# CC13x0 register map
File version: 2.0
CPU: CM3 r2p1, little endian, no MPU, no FPU, 0x3 interrupt priority bits, 0x0 interrupts
Registers are 32-bit, read-write, reset 0x0 unless marked. A register's access mark holds for its fields unless they carry their own. Offsets are from the block's base; [hi:lo] are bit positions; {n}, {i} and the like mark numbered series; 'fields as' and 'values as' point back to an identical list.

## FCFG1 — Factory configuration area (FCFG1)
Base 0x50001000
0xA0 MISC_CONF_1 ro reset 0xFFFFFF00 — Misc configurations
  [7:0] DEVICE_MINOR_REV
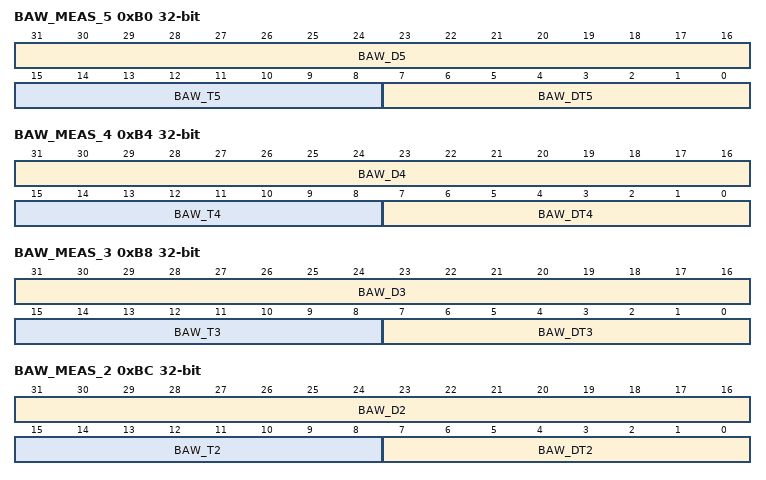
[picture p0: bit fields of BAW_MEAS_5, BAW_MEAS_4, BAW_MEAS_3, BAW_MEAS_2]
0xB0 BAW_MEAS_5 ro — Internal. Only to be used through TI provided API.
  [31:16] BAW_D5, [15:8] BAW_T5, [7:0] BAW_DT5
0xB4 BAW_MEAS_4 ro — Internal. Only to be used through TI provided API.
  [31:16] BAW_D4, [15:8] BAW_T4, [7:0] BAW_DT4
0xB8 BAW_MEAS_3 ro — Internal. Only to be used through TI provided API.
  [31:16] BAW_D3, [15:8] BAW_T3, [7:0] BAW_DT3
0xBC BAW_MEAS_2 ro — Internal. Only to be used through TI provided API.
  [31:16] BAW_D2, [15:8] BAW_T2, [7:0] BAW_DT2
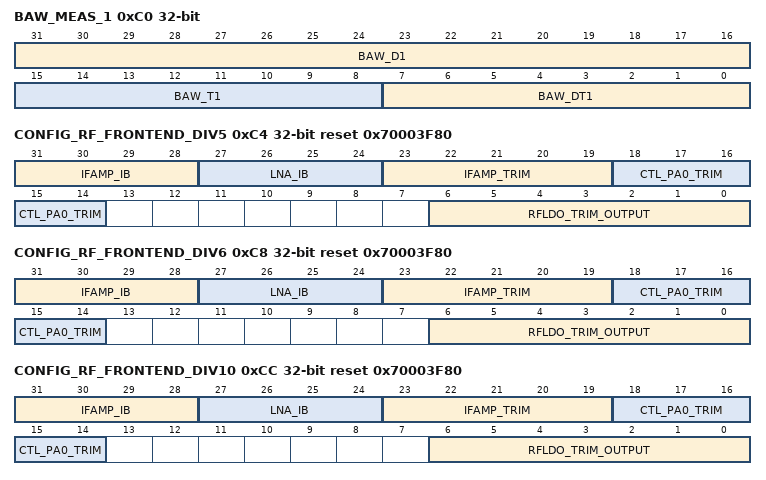
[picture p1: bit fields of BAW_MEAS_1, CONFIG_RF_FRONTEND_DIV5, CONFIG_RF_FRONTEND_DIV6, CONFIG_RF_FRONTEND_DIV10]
0xC0 BAW_MEAS_1 ro — Internal. Only to be used through TI provided API.
  [31:16] BAW_D1, [15:8] BAW_T1, [7:0] BAW_DT1
0xC4 CONFIG_RF_FRONTEND_DIV5 ro reset 0x70003F80 — Internal. Only to be used through TI provided API.
  [31:28] IFAMP_IB, [27:24] LNA_IB, [23:19] IFAMP_TRIM, [18:14] CTL_PA0_TRIM, [6:0] RFLDO_TRIM_OUTPUT
0xC8 CONFIG_RF_FRONTEND_DIV6 ro reset 0x70003F80 — Internal. Only to be used through TI provided API.
  fields as CONFIG_RF_FRONTEND_DIV5
0xCC CONFIG_RF_FRONTEND_DIV10 ro reset 0x70003F80 — Internal. Only to be used through TI provided API.
  fields as CONFIG_RF_FRONTEND_DIV5
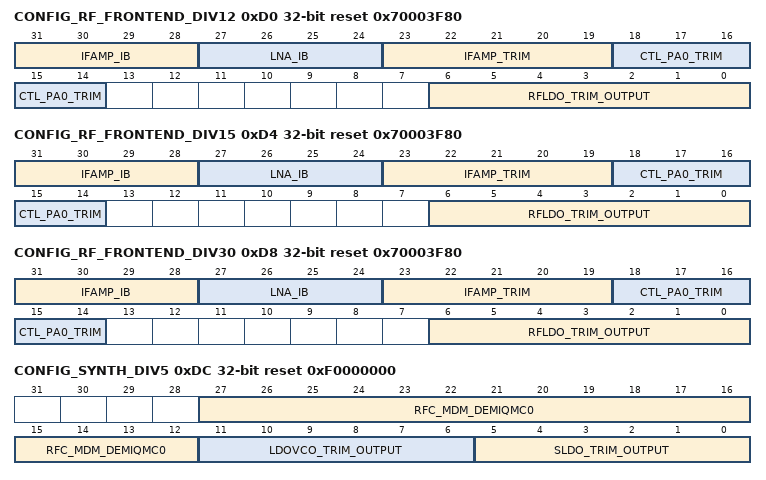
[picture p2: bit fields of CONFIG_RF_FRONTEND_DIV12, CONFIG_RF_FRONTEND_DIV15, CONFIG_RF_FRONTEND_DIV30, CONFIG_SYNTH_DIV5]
0xD0 CONFIG_RF_FRONTEND_DIV12 ro reset 0x70003F80 — Internal. Only to be used through TI provided API.
  fields as CONFIG_RF_FRONTEND_DIV5
0xD4 CONFIG_RF_FRONTEND_DIV15 ro reset 0x70003F80 — Internal. Only to be used through TI provided API.
  fields as CONFIG_RF_FRONTEND_DIV5
0xD8 CONFIG_RF_FRONTEND_DIV30 ro reset 0x70003F80 — Internal. Only to be used through TI provided API.
  fields as CONFIG_RF_FRONTEND_DIV5
0xDC CONFIG_SYNTH_DIV5 ro reset 0xF0000000 — Internal. Only to be used through TI provided API.
  [27:12] RFC_MDM_DEMIQMC0, [11:6] LDOVCO_TRIM_OUTPUT, [5:0] SLDO_TRIM_OUTPUT
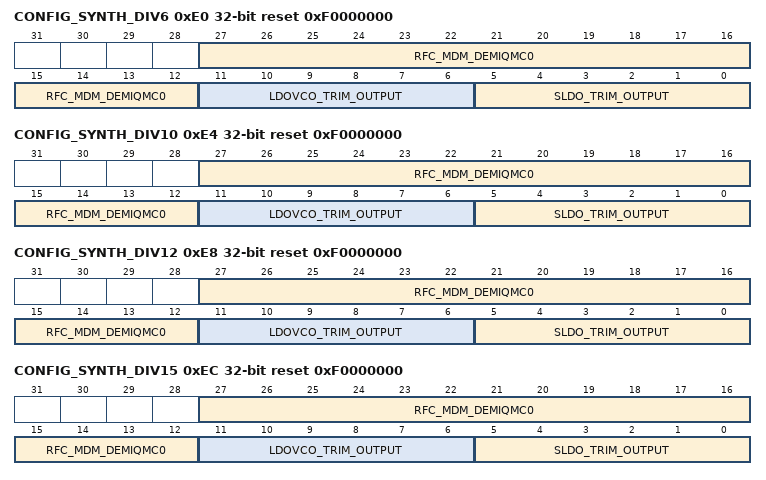
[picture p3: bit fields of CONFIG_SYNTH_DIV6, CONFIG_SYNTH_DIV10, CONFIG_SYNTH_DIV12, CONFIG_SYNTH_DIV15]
0xE0 CONFIG_SYNTH_DIV6 ro reset 0xF0000000 — Internal. Only to be used through TI provided API.
  fields as CONFIG_SYNTH_DIV5
0xE4 CONFIG_SYNTH_DIV10 ro reset 0xF0000000 — Internal. Only to be used through TI provided API.
  fields as CONFIG_SYNTH_DIV5
0xE8 CONFIG_SYNTH_DIV12 ro reset 0xF0000000 — Internal. Only to be used through TI provided API.
  fields as CONFIG_SYNTH_DIV5
0xEC CONFIG_SYNTH_DIV15 ro reset 0xF0000000 — Internal. Only to be used through TI provided API.
  fields as CONFIG_SYNTH_DIV5
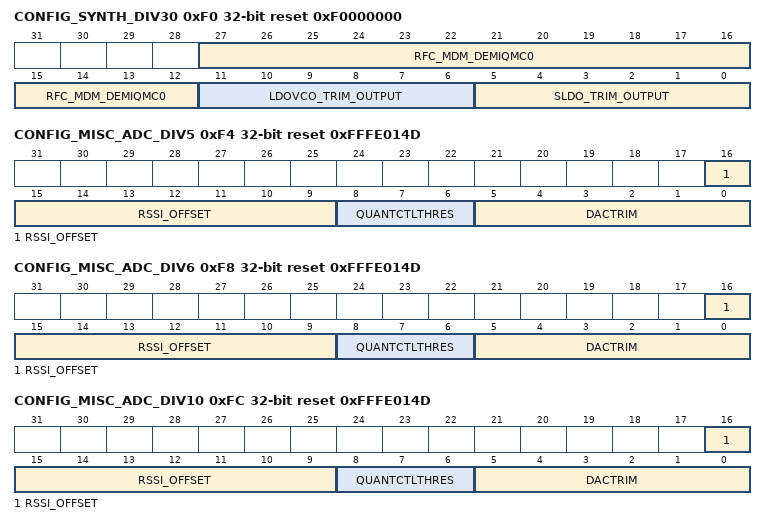
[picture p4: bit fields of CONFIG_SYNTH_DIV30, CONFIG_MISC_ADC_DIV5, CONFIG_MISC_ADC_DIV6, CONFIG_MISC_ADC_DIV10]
0xF0 CONFIG_SYNTH_DIV30 ro reset 0xF0000000 — Internal. Only to be used through TI provided API.
  fields as CONFIG_SYNTH_DIV5
0xF4 CONFIG_MISC_ADC_DIV5 ro reset 0xFFFE014D — Internal. Only to be used through TI provided API.
  [16:9] RSSI_OFFSET, [8:6] QUANTCTLTHRES, [5:0] DACTRIM
0xF8 CONFIG_MISC_ADC_DIV6 ro reset 0xFFFE014D — Internal. Only to be used through TI provided API.
  [16:9] RSSI_OFFSET, [8:6] QUANTCTLTHRES, [5:0] DACTRIM
0xFC CONFIG_MISC_ADC_DIV10 ro reset 0xFFFE014D — Internal. Only to be used through TI provided API.
  [16:9] RSSI_OFFSET, [8:6] QUANTCTLTHRES, [5:0] DACTRIM
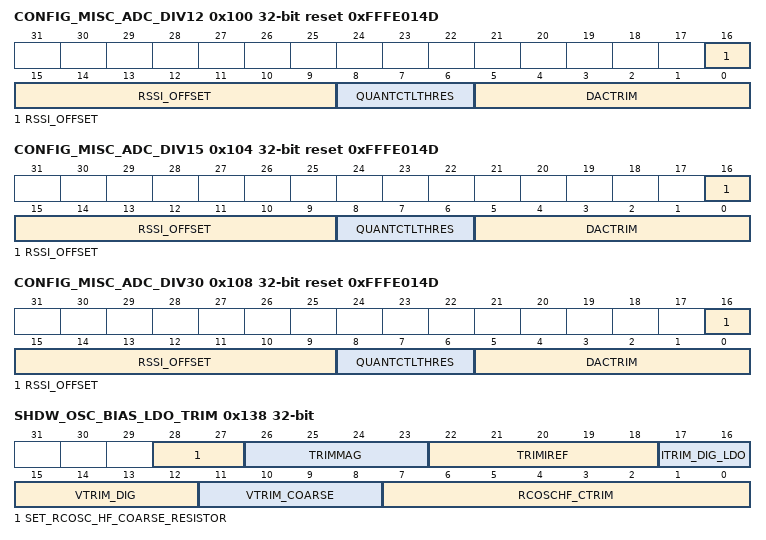
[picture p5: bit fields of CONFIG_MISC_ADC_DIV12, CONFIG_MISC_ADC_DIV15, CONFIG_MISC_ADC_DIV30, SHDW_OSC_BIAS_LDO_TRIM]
0x100 CONFIG_MISC_ADC_DIV12 ro reset 0xFFFE014D — Internal. Only to be used through TI provided API.
  [16:9] RSSI_OFFSET, [8:6] QUANTCTLTHRES, [5:0] DACTRIM
0x104 CONFIG_MISC_ADC_DIV15 ro reset 0xFFFE014D — Internal. Only to be used through TI provided API.
  [16:9] RSSI_OFFSET, [8:6] QUANTCTLTHRES, [5:0] DACTRIM
0x108 CONFIG_MISC_ADC_DIV30 ro reset 0xFFFE014D — Internal. Only to be used through TI provided API.
  [16:9] RSSI_OFFSET, [8:6] QUANTCTLTHRES, [5:0] DACTRIM
{0x118+4i} SHDW_DIE_ID_{i} ro (i=0..3) — Shadow of the DIE_ID_{i} register in eFuse
  [31:0] ID_{32i+31}_{32i}
0x138 SHDW_OSC_BIAS_LDO_TRIM ro — Internal. Only to be used through TI provided API.
  [28:27] SET_RCOSC_HF_COARSE_RESISTOR, [26:23] TRIMMAG, [22:18] TRIMIREF, [17:16] ITRIM_DIG_LDO, [15:12] VTRIM_DIG, [11:8] VTRIM_COARSE, [7:0] RCOSCHF_CTRIM
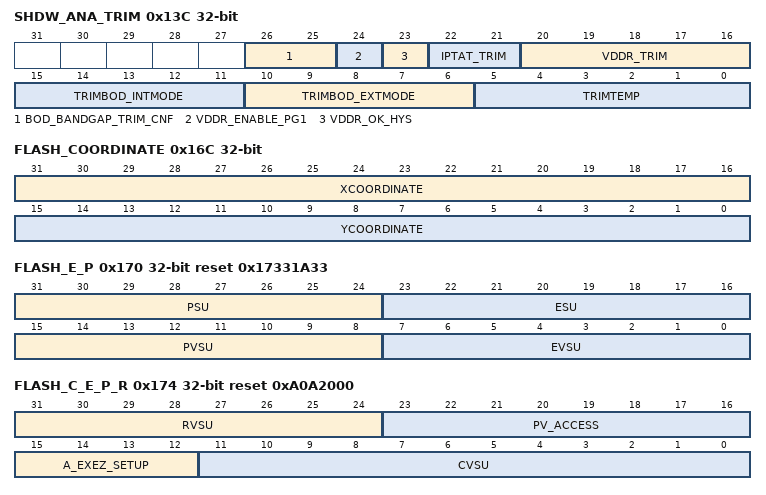
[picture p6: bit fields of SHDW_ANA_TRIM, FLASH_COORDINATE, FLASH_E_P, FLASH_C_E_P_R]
0x13C SHDW_ANA_TRIM ro — Internal. Only to be used through TI provided API.
  [26:25] BOD_BANDGAP_TRIM_CNF, [24] VDDR_ENABLE_PG1, [23] VDDR_OK_HYS, [22:21] IPTAT_TRIM, [20:16] VDDR_TRIM, [15:11] TRIMBOD_INTMODE, [10:6] TRIMBOD_EXTMODE, [5:0] TRIMTEMP
0x164 FLASH_NUMBER ro
  [31:0] LOT_NUMBER
0x16C FLASH_COORDINATE ro
  [31:16] XCOORDINATE, [15:0] YCOORDINATE
0x170 FLASH_E_P ro reset 0x17331A33 — Internal. Only to be used through TI provided API.
  [31:24] PSU, [23:16] ESU, [15:8] PVSU, [7:0] EVSU
0x174 FLASH_C_E_P_R ro reset 0xA0A2000 — Internal. Only to be used through TI provided API.
  [31:24] RVSU, [23:16] PV_ACCESS, [15:12] A_EXEZ_SETUP, [11:0] CVSU
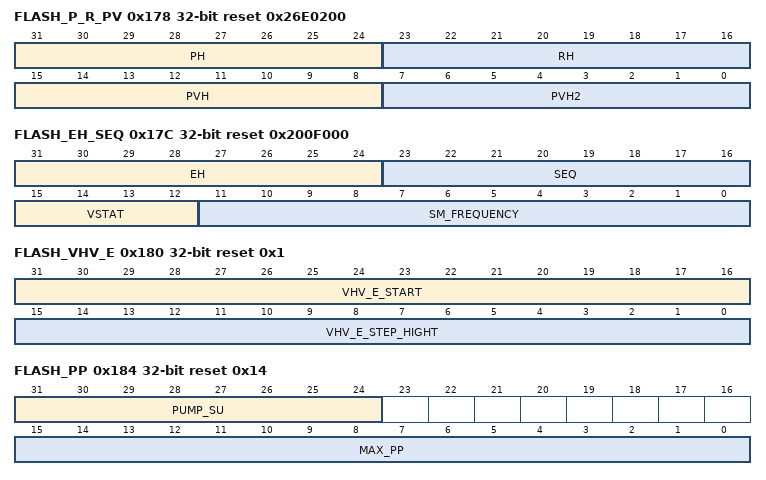
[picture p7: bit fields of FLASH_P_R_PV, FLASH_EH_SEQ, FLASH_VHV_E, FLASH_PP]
0x178 FLASH_P_R_PV ro reset 0x26E0200 — Internal. Only to be used through TI provided API.
  [31:24] PH, [23:16] RH, [15:8] PVH, [7:0] PVH2
0x17C FLASH_EH_SEQ ro reset 0x200F000 — Internal. Only to be used through TI provided API.
  [31:24] EH, [23:16] SEQ, [15:12] VSTAT, [11:0] SM_FREQUENCY
0x180 FLASH_VHV_E ro reset 0x1 — Internal. Only to be used through TI provided API.
  [31:16] VHV_E_START, [15:0] VHV_E_STEP_HIGHT
0x184 FLASH_PP ro reset 0x14 — Internal. Only to be used through TI provided API.
  [31:24] PUMP_SU, [15:0] MAX_PP
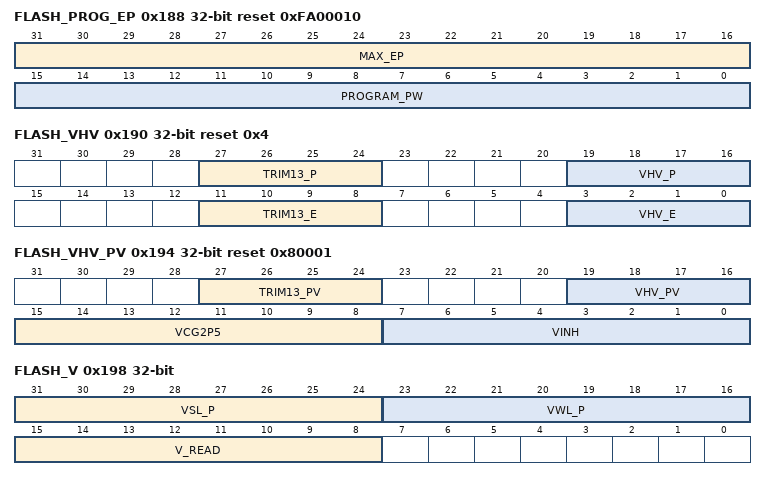
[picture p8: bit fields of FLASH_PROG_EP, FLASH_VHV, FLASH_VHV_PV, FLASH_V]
0x188 FLASH_PROG_EP ro reset 0xFA00010 — Internal. Only to be used through TI provided API.
  [31:16] MAX_EP, [15:0] PROGRAM_PW
0x18C FLASH_ERA_PW ro reset 0xFA0 — Internal. Only to be used through TI provided API.
  [31:0] ERASE_PW
0x190 FLASH_VHV ro reset 0x4 — Internal. Only to be used through TI provided API.
  [27:24] TRIM13_P, [19:16] VHV_P, [11:8] TRIM13_E, [3:0] VHV_E
0x194 FLASH_VHV_PV ro reset 0x80001 — Internal. Only to be used through TI provided API.
  [27:24] TRIM13_PV, [19:16] VHV_PV, [15:8] VCG2P5, [7:0] VINH
0x198 FLASH_V ro — Internal. Only to be used through TI provided API.
  [31:24] VSL_P, [23:16] VWL_P, [15:8] V_READ
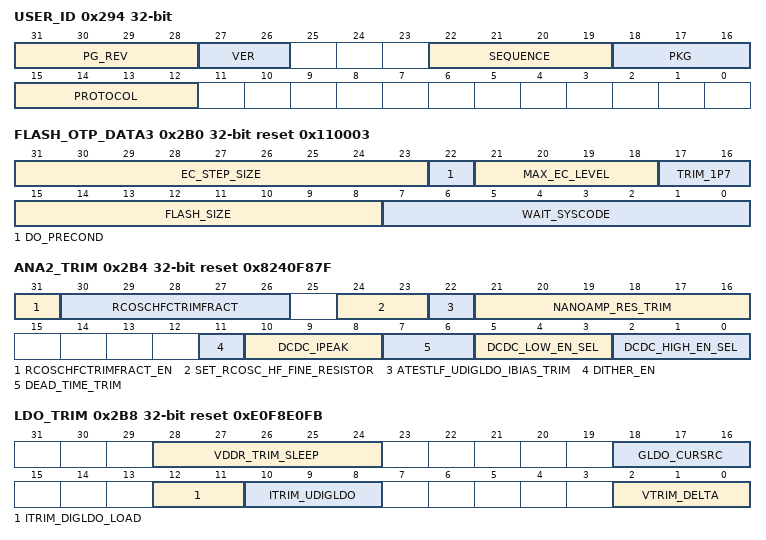
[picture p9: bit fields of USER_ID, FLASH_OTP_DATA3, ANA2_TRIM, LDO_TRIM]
0x294 USER_ID ro — User Identification. Reading this register or the ICEPICK_DEVICE_ID register is the only support way of identifying a device. The value of this register will be written to AON_WUC:JTAGUSERCODE by boot FW while in safezone.
  [31:28] PG_REV, [27:26] VER, [22:19] SEQUENCE, [18:16] PKG, [15:12] PROTOCOL
0x2B0 FLASH_OTP_DATA3 ro reset 0x110003 — Internal. Only to be used through TI provided API.
  [31:23] EC_STEP_SIZE, [22] DO_PRECOND, [21:18] MAX_EC_LEVEL, [17:16] TRIM_1P7, [15:8] FLASH_SIZE, [7:0] WAIT_SYSCODE
0x2B4 ANA2_TRIM ro reset 0x8240F87F — Internal. Only to be used through TI provided API.
  [31] RCOSCHFCTRIMFRACT_EN, [30:26] RCOSCHFCTRIMFRACT, [24:23] SET_RCOSC_HF_FINE_RESISTOR, [22] ATESTLF_UDIGLDO_IBIAS_TRIM, [21:16] NANOAMP_RES_TRIM, [11] DITHER_EN, [10:8] DCDC_IPEAK, [7:6] DEAD_TIME_TRIM, [5:3] DCDC_LOW_EN_SEL, [2:0] DCDC_HIGH_EN_SEL
0x2B8 LDO_TRIM ro reset 0xE0F8E0FB — Internal. Only to be used through TI provided API.
  [28:24] VDDR_TRIM_SLEEP, [18:16] GLDO_CURSRC, [12:11] ITRIM_DIGLDO_LOAD, [10:8] ITRIM_UDIGLDO, [2:0] VTRIM_DELTA
0x2E8 MAC_BLE_0 ro — MAC BLE Address 0
  [31:0] ADDR_0_31
0x2EC MAC_BLE_1 ro — MAC BLE Address 1
  [31:0] ADDR_32_63
0x2F0 MAC_15_4_0 ro — MAC IEEE 802.15.4 Address 0
  [31:0] ADDR_0_31
0x2F4 MAC_15_4_1 ro — MAC IEEE 802.15.4 Address 1
  [31:0] ADDR_32_63
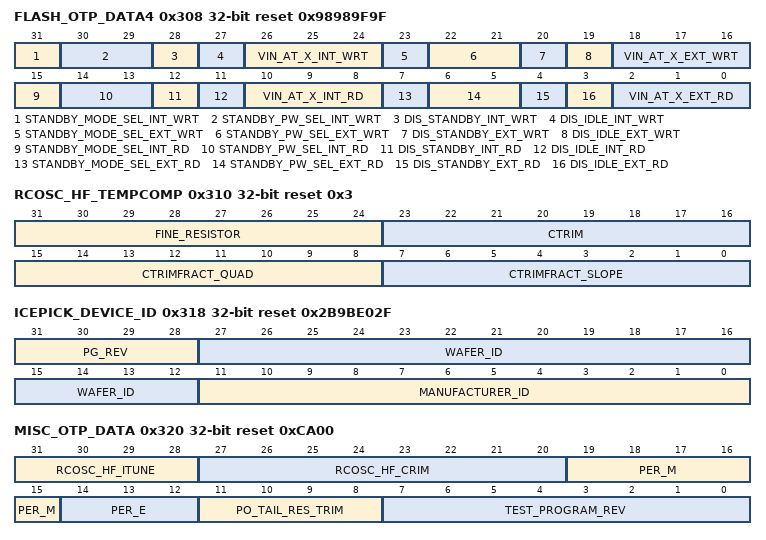
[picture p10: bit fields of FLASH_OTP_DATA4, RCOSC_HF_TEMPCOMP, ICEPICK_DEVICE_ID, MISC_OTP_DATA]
0x308 FLASH_OTP_DATA4 ro reset 0x98989F9F — Internal. Only to be used through TI provided API.
  [31] STANDBY_MODE_SEL_INT_WRT, [30:29] STANDBY_PW_SEL_INT_WRT, [28] DIS_STANDBY_INT_WRT, [27] DIS_IDLE_INT_WRT, [26:24] VIN_AT_X_INT_WRT, [23] STANDBY_MODE_SEL_EXT_WRT, [22:21] STANDBY_PW_SEL_EXT_WRT, [20] DIS_STANDBY_EXT_WRT, [19] DIS_IDLE_EXT_WRT, [18:16] VIN_AT_X_EXT_WRT, [15] STANDBY_MODE_SEL_INT_RD, [14:13] STANDBY_PW_SEL_INT_RD, [12] DIS_STANDBY_INT_RD, [11] DIS_IDLE_INT_RD, [10:8] VIN_AT_X_INT_RD, [7] STANDBY_MODE_SEL_EXT_RD, [6:5] STANDBY_PW_SEL_EXT_RD, [4] DIS_STANDBY_EXT_RD, [3] DIS_IDLE_EXT_RD, [2:0] VIN_AT_X_EXT_RD
0x30C MISC_TRIM ro reset 0xFFFFFF33 — Miscellaneous Trim Parameters
  [7:0] TEMPVSLOPE
0x310 RCOSC_HF_TEMPCOMP ro reset 0x3 — Internal. Only to be used through TI provided API.
  [31:24] FINE_RESISTOR, [23:16] CTRIM, [15:8] CTRIMFRACT_QUAD, [7:0] CTRIMFRACT_SLOPE
0x318 ICEPICK_DEVICE_ID ro reset 0x2B9BE02F — IcePick Device Identification Reading this register or the USER_ID register is the only support way of identifying a device.
  [31:28] PG_REV, [27:12] WAFER_ID, [11:0] MANUFACTURER_ID
0x31C FCFG1_REVISION ro reset 0x24 — Factory Configuration (FCFG1) Revision
  [31:0] REV
0x320 MISC_OTP_DATA ro reset 0xCA00
  [31:28] RCOSC_HF_ITUNE, [27:20] RCOSC_HF_CRIM, [19:15] PER_M, [14:12] PER_E, [11:8] PO_TAIL_RES_TRIM, [7:0] TEST_PROGRAM_REV
0x344 IOCONF ro reset 0x7FFFFF8000 — IO Configuration
  [6:0] GPIO_CNT
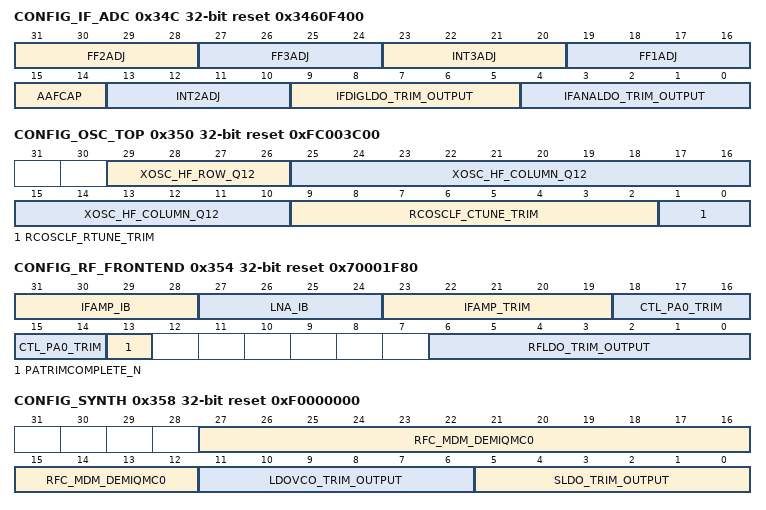
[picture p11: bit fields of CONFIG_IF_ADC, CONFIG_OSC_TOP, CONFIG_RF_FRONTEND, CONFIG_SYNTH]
0x34C CONFIG_IF_ADC ro reset 0x3460F400 — Internal. Only to be used through TI provided API.
  [31:28] FF2ADJ, [27:24] FF3ADJ, [23:20] INT3ADJ, [19:16] FF1ADJ, [15:14] AAFCAP, [13:10] INT2ADJ, [9:5] IFDIGLDO_TRIM_OUTPUT, [4:0] IFANALDO_TRIM_OUTPUT
0x350 CONFIG_OSC_TOP ro reset 0xFC003C00 — Internal. Only to be used through TI provided API.
  [29:26] XOSC_HF_ROW_Q12, [25:10] XOSC_HF_COLUMN_Q12, [9:2] RCOSCLF_CTUNE_TRIM, [1:0] RCOSCLF_RTUNE_TRIM
0x354 CONFIG_RF_FRONTEND ro reset 0x70001F80 — Internal. Only to be used through TI provided API.
  [31:28] IFAMP_IB, [27:24] LNA_IB, [23:19] IFAMP_TRIM, [18:14] CTL_PA0_TRIM, [13] PATRIMCOMPLETE_N, [6:0] RFLDO_TRIM_OUTPUT
0x358 CONFIG_SYNTH ro reset 0xF0000000 — Internal. Only to be used through TI provided API.
  fields as CONFIG_SYNTH_DIV5
0x35C SOC_ADC_ABS_GAIN ro reset 0xFFFF0000 — AUX_ADC Gain in Absolute Reference Mode
  [15:0] SOC_ADC_ABS_GAIN_TEMP1
0x360 SOC_ADC_REL_GAIN ro reset 0xFFFF0000 — AUX_ADC Gain in Relative Reference Mode
  [15:0] SOC_ADC_REL_GAIN_TEMP1
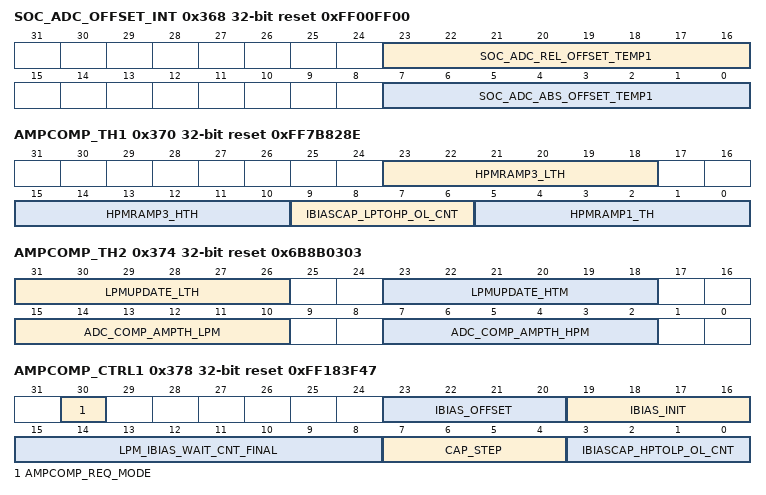
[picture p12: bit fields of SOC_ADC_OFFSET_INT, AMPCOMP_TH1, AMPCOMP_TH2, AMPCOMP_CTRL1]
0x368 SOC_ADC_OFFSET_INT ro reset 0xFF00FF00 — AUX_ADC Temperature Offsets in Absolute Reference Mode
  [23:16] SOC_ADC_REL_OFFSET_TEMP1, [7:0] SOC_ADC_ABS_OFFSET_TEMP1
0x36C SOC_ADC_REF_TRIM_AND_OFFSET_EXT ro reset 0x3FFFFFC080 — Internal. Only to be used through TI provided API.
  [5:0] SOC_ADC_REF_VOLTAGE_TRIM_TEMP1
0x370 AMPCOMP_TH1 ro reset 0xFF7B828E — Internal. Only to be used through TI provided API.
  [23:18] HPMRAMP3_LTH, [15:10] HPMRAMP3_HTH, [9:6] IBIASCAP_LPTOHP_OL_CNT, [5:0] HPMRAMP1_TH
0x374 AMPCOMP_TH2 ro reset 0x6B8B0303 — Internal. Only to be used through TI provided API.
  [31:26] LPMUPDATE_LTH, [23:18] LPMUPDATE_HTM, [15:10] ADC_COMP_AMPTH_LPM, [7:2] ADC_COMP_AMPTH_HPM
0x378 AMPCOMP_CTRL1 ro reset 0xFF183F47 — Internal. Only to be used through TI provided API.
  [30] AMPCOMP_REQ_MODE, [23:20] IBIAS_OFFSET, [19:16] IBIAS_INIT, [15:8] LPM_IBIAS_WAIT_CNT_FINAL, [7:4] CAP_STEP, [3:0] IBIASCAP_HPTOLP_OL_CNT
0x37C ANABYPASS_VALUE2 ro reset 0xFFFFC3FF — Internal. Only to be used through TI provided API.
  [13:0] XOSC_HF_IBIASTHERM
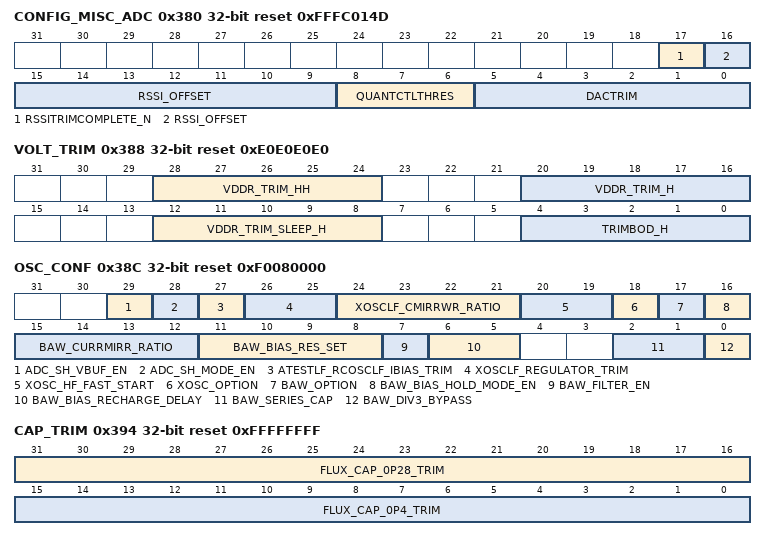
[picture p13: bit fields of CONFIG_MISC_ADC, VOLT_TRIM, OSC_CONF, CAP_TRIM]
0x380 CONFIG_MISC_ADC ro reset 0xFFFC014D — Internal. Only to be used through TI provided API.
  [17] RSSITRIMCOMPLETE_N, [16:9] RSSI_OFFSET, [8:6] QUANTCTLTHRES, [5:0] DACTRIM
0x388 VOLT_TRIM ro reset 0xE0E0E0E0 — Internal. Only to be used through TI provided API.
  [28:24] VDDR_TRIM_HH, [20:16] VDDR_TRIM_H, [12:8] VDDR_TRIM_SLEEP_H, [4:0] TRIMBOD_H
0x38C OSC_CONF ro reset 0xF0080000 — OSC Configuration
  [29] ADC_SH_VBUF_EN, [28] ADC_SH_MODE_EN, [27] ATESTLF_RCOSCLF_IBIAS_TRIM, [26:25] XOSCLF_REGULATOR_TRIM, [24:21] XOSCLF_CMIRRWR_RATIO, [20:19] XOSC_HF_FAST_START, [18] XOSC_OPTION, [17] BAW_OPTION, [16] BAW_BIAS_HOLD_MODE_EN, [15:12] BAW_CURRMIRR_RATIO, [11:8] BAW_BIAS_RES_SET, [7] BAW_FILTER_EN, [6:5] BAW_BIAS_RECHARGE_DELAY, [2:1] BAW_SERIES_CAP, [0] BAW_DIV3_BYPASS
0x394 CAP_TRIM ro reset 0xFFFFFFFF — Internal. Only to be used through TI provided API.
  [31:16] FLUX_CAP_0P28_TRIM, [15:0] FLUX_CAP_0P4_TRIM
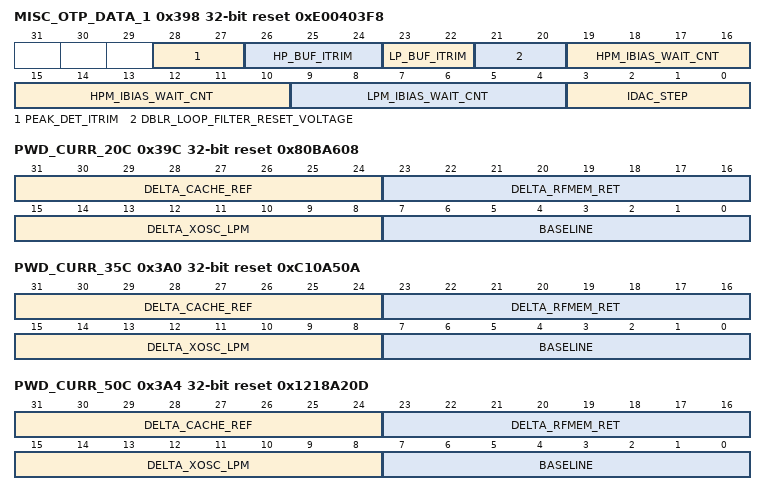
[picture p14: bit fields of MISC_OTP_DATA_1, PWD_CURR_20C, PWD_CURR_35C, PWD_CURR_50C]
0x398 MISC_OTP_DATA_1 ro reset 0xE00403F8 — Internal. Only to be used through TI provided API.
  [28:27] PEAK_DET_ITRIM, [26:24] HP_BUF_ITRIM, [23:22] LP_BUF_ITRIM, [21:20] DBLR_LOOP_FILTER_RESET_VOLTAGE, [19:10] HPM_IBIAS_WAIT_CNT, [9:4] LPM_IBIAS_WAIT_CNT, [3:0] IDAC_STEP
0x39C PWD_CURR_20C ro reset 0x80BA608 — Power Down Current Control 20C
  [31:24] DELTA_CACHE_REF, [23:16] DELTA_RFMEM_RET, [15:8] DELTA_XOSC_LPM, [7:0] BASELINE
0x3A0 PWD_CURR_35C ro reset 0xC10A50A — Power Down Current Control 35C
  fields as PWD_CURR_20C
0x3A4 PWD_CURR_50C ro reset 0x1218A20D — Power Down Current Control 50C
  fields as PWD_CURR_20C
0x3A8 PWD_CURR_65C ro reset 0x1C259C14 — Power Down Current Control 65C
  fields as PWD_CURR_20C
0x3AC PWD_CURR_80C ro reset 0x2E3B9021 — Power Down Current Control 80C
  fields as PWD_CURR_20C
0x3B0 PWD_CURR_95C ro reset 0x4C627A3B — Power Down Current Control 95C
  fields as PWD_CURR_20C
0x3B4 PWD_CURR_110C ro reset 0x789E706B — Power Down Current Control 110C
  fields as PWD_CURR_20C
0x3B8 PWD_CURR_125C ro reset 0xADE1809A — Power Down Current Control 125C
  fields as PWD_CURR_20C
